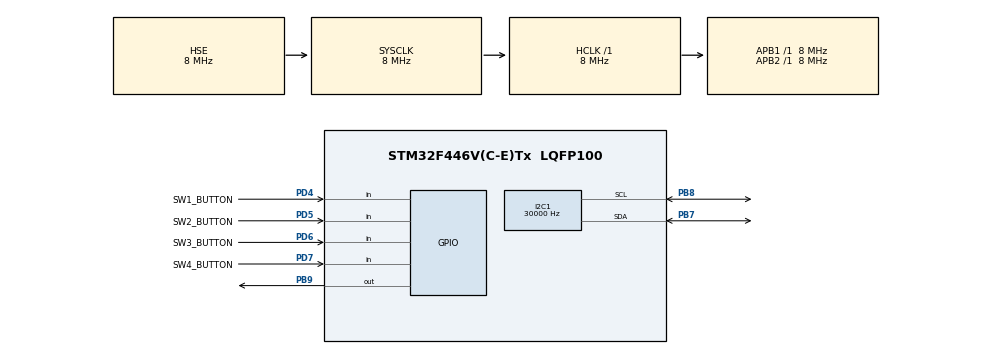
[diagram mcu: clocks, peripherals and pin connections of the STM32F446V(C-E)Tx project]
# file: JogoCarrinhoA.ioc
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I2C1.ClockSpeed=30000
Mcu.Family=STM32F4
Mcu.Name=STM32F446V(C-E)Tx
Mcu.Package=LQFP100
NVIC.PriorityGroup=NVIC_PRIORITYGROUP_4
PB7.Mode=I2C
PB7.Signal=I2C1_SDA
PB8.Mode=I2C
PB8.Signal=I2C1_SCL
PB9.Signal=GPIO_Output
PD4.GPIO_Label=SW1_BUTTON
PD4.GPIO_PuPd=GPIO_PULLUP
PD4.Signal=GPIO_Input
PD5.GPIO_Label=SW2_BUTTON
PD5.GPIO_PuPd=GPIO_PULLUP
PD5.Signal=GPIO_Input
PD6.GPIO_Label=SW3_BUTTON
PD6.GPIO_PuPd=GPIO_PULLUP
PD6.Signal=GPIO_Input
PD7.GPIO_Label=SW4_BUTTON
PD7.GPIO_PuPd=GPIO_PULLUP
PD7.Signal=GPIO_Input
PH0-OSC_IN.Mode=HSE-External-Oscillator
PH0-OSC_IN.Signal=RCC_OSC_IN
PH1-OSC_OUT.Mode=HSE-External-Oscillator
PH1-OSC_OUT.Signal=RCC_OSC_OUT
ProjectManager.HeapSize=0x200
ProjectManager.StackSize=0x400
ProjectManager.TargetToolchain=TrueSTUDIO
RCC.AHBFreq_Value=8000000
RCC.APB1Freq_Value=8000000
RCC.APB1TimFreq_Value=8000000
RCC.APB2Freq_Value=8000000
RCC.APB2TimFreq_Value=8000000
RCC.CortexFreq_Value=8000000
RCC.HCLKFreq_Value=8000000
RCC.HSE_VALUE=8000000
RCC.PLLSourceVirtual=RCC_PLLSOURCE_HSE
RCC.SYSCLKFreq_VALUE=8000000
RCC.SYSCLKSource=RCC_SYSCLKSOURCE_HSE
RCC.USBFreq_Value=48000000
RCC.VCOOutputFreq_Value=96000000
board=JogoCarrinhoA

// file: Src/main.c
/**
  ******************************************************************************
  * File Name          : main.c
  * Description        : Main program body
  ******************************************************************************
  *
  * COPYRIGHT(c) 2017 STMicroelectronics
  *
  * Redistribution and use in source and binary forms, with or without modification,
  * are permitted provided that the following conditions are met:
  *   1. Redistributions of source code must retain the above copyright notice,
  *      this list of conditions and the following disclaimer.
  *   2. Redistributions in binary form must reproduce the above copyright notice,
  *      this list of conditions and the following disclaimer in the documentation
  *      and/or other materials provided with the distribution.
  *   3. Neither the name of STMicroelectronics nor the names of its contributors
  *      may be used to endorse or promote products derived from this software
  *      without specific prior written permission.
  *
  * THIS SOFTWARE IS PROVIDED BY THE COPYRIGHT HOLDERS AND CONTRIBUTORS "AS IS"
  * AND ANY EXPRESS OR IMPLIED WARRANTIES, INCLUDING, BUT NOT LIMITED TO, THE
  * IMPLIED WARRANTIES OF MERCHANTABILITY AND FITNESS FOR A PARTICULAR PURPOSE ARE
  * DISCLAIMED. IN NO EVENT SHALL THE COPYRIGHT HOLDER OR CONTRIBUTORS BE LIABLE
  * FOR ANY DIRECT, INDIRECT, INCIDENTAL, SPECIAL, EXEMPLARY, OR CONSEQUENTIAL
  * DAMAGES (INCLUDING, BUT NOT LIMITED TO, PROCUREMENT OF SUBSTITUTE GOODS OR
  * SERVICES; LOSS OF USE, DATA, OR PROFITS; OR BUSINESS INTERRUPTION) HOWEVER
  * CAUSED AND ON ANY THEORY OF LIABILITY, WHETHER IN CONTRACT, STRICT LIABILITY,
  * OR TORT (INCLUDING NEGLIGENCE OR OTHERWISE) ARISING IN ANY WAY OUT OF THE USE
  * OF THIS SOFTWARE, EVEN IF ADVISED OF THE POSSIBILITY OF SUCH DAMAGE.
  *
  ******************************************************************************
  */
#include "stm32f4xx_hal.h"
#include "i2c.h"
#include "gpio.h"

/* USER CODE BEGIN Includes */
#include "car_game_definitions.h"
/* USER CODE END Includes */

/* USER CODE BEGIN PV */
/* Private variables ---------------------------------------------------------*/

/* USER CODE END PV */

void SystemClock_Config(void);
void Error_Handler(void);

/* USER CODE BEGIN PFP */
/* Private function prototypes -----------------------------------------------*/

/* USER CODE END PFP */

int main(void)
{

  /* MCU Configuration----------------------------------------------------------*/

  /* Reset of all peripherals, Initializes the Flash interface and the Systick. */
  HAL_Init();

  /* Configure the system clock */
  SystemClock_Config();

  /* Initialize all configured peripherals */
  MX_GPIO_Init();
  MX_I2C1_Init();
  SystemClock_Config();

  /* USER CODE BEGIN 2 */
	activate_display();

    display_cmd_delay(50);

	create_cars_characters();

    display_cmd_delay(50);

	clear_display();

	Level level = {level:1,cars_qtd:30,cars_speed:2400,cols_until_new_car:5,score:0};

  /* USER CODE END 2 */

  /* Infinite loop */
  /* USER CODE BEGIN WHILE */
  while (execute_level(&level)) {

  /* USER CODE END WHILE */

  /* USER CODE BEGIN 3 */
	  // Progressão de level

	  level.level++;
	  level.cars_speed = 50*level.cars_speed/100;
	  level.cars_qtd += 5;

	  if (level.cols_until_new_car > 2) {
		  level.cols_until_new_car--;
	  }

  }
  /* USER CODE END 3 */

}

/** System Clock Configuration
*/
void SystemClock_Config(void)
{

  RCC_OscInitTypeDef RCC_OscInitStruct;
  RCC_ClkInitTypeDef RCC_ClkInitStruct;

  __HAL_RCC_PWR_CLK_ENABLE();

  __HAL_PWR_VOLTAGESCALING_CONFIG(PWR_REGULATOR_VOLTAGE_SCALE3);

  RCC_OscInitStruct.OscillatorType = RCC_OSCILLATORTYPE_HSE;
  RCC_OscInitStruct.HSEState = RCC_HSE_ON;
  RCC_OscInitStruct.PLL.PLLState = RCC_PLL_NONE;
  if (HAL_RCC_OscConfig(&RCC_OscInitStruct) != HAL_OK)
  {
    Error_Handler();
  }

  RCC_ClkInitStruct.ClockType = RCC_CLOCKTYPE_HCLK|RCC_CLOCKTYPE_SYSCLK
                              |RCC_CLOCKTYPE_PCLK1|RCC_CLOCKTYPE_PCLK2;
  RCC_ClkInitStruct.SYSCLKSource = RCC_SYSCLKSOURCE_HSE;
  RCC_ClkInitStruct.AHBCLKDivider = RCC_SYSCLK_DIV1;
  RCC_ClkInitStruct.APB1CLKDivider = RCC_HCLK_DIV1;
  RCC_ClkInitStruct.APB2CLKDivider = RCC_HCLK_DIV1;
  if (HAL_RCC_ClockConfig(&RCC_ClkInitStruct, FLASH_LATENCY_0) != HAL_OK)
  {
    Error_Handler();
  }

  HAL_SYSTICK_Config(HAL_RCC_GetHCLKFreq()/1000);

  HAL_SYSTICK_CLKSourceConfig(SYSTICK_CLKSOURCE_HCLK);

  /* SysTick_IRQn interrupt configuration */
  HAL_NVIC_SetPriority(SysTick_IRQn, 0, 0);
}

void Error_Handler(void)
{
  while(1)
  {
  }
}

/************************ (C) COPYRIGHT STMicroelectronics *****END OF FILE****/
